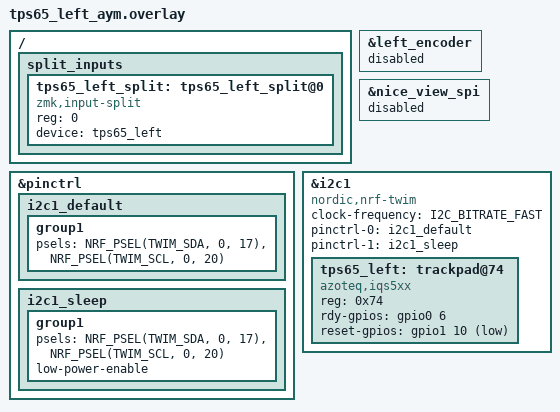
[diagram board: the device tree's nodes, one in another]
/*
 * Azoteq TPS65 (IQS550, I2C 0x74) on the left half (task 07), AYM1607 driver
 * (compatible "azoteq,iqs5xx"), as tps65_right_aym.
 * Pins (task 07 step 1, D2 left): the 5 display pads are the same as on the right:
 *   SDA = P0.17 (P1), SCL = P0.20 (P4), RDY = P0.06 (P3).
 * The left PCB has no expansion header, so RST = P1.10 on the roller footprint
 * (hole H3 or H5). The roller (left_encoder, P1.10/P1.14) is off here.
 * Version D has no display: spi0 (nice!view) is off and its pins go to i2c1.
 * Never build this with nice_view, and keep CONFIG_ZMK_DISPLAY=n: the display's
 * CS on P0.06 would drive the pad's RDY output.
 */

#include <zephyr/dt-bindings/gpio/gpio.h>

&left_encoder {
    status = "disabled";
};

&nice_view_spi {
    status = "disabled";
};

&pinctrl {
    i2c1_default: i2c1_default {
        group1 {
            psels = <NRF_PSEL(TWIM_SDA, 0, 17)>,
                    <NRF_PSEL(TWIM_SCL, 0, 20)>;
        };
    };

    i2c1_sleep: i2c1_sleep {
        group1 {
            psels = <NRF_PSEL(TWIM_SDA, 0, 17)>,
                    <NRF_PSEL(TWIM_SCL, 0, 20)>;
            low-power-enable;
        };
    };
};

&i2c1 {
    status = "okay";
    compatible = "nordic,nrf-twim";
    clock-frequency = <I2C_BITRATE_FAST>;
    pinctrl-0 = <&i2c1_default>;
    pinctrl-1 = <&i2c1_sleep>;
    pinctrl-names = "default", "sleep";

    tps65_left: trackpad@74 {
        compatible = "azoteq,iqs5xx";
        reg = <0x74>;
        status = "okay";

        rdy-gpios = <&gpio0 6 GPIO_ACTIVE_HIGH>;
        /* RST is active low; this driver uses the active-low flag (see its README). */
        reset-gpios = <&gpio1 10 GPIO_ACTIVE_LOW>;

        /* No gestures: no taps, press-and-hold or scroll. The pad only reports X/Y. */
    };
};

/ {
    split_inputs {
        #address-cells = <1>;
        #size-cells = <0>;

        tps65_left_split: tps65_left_split@0 {
            compatible = "zmk,input-split";
            reg = <0>;
            device = <&tps65_left>;
        };
    };
};
